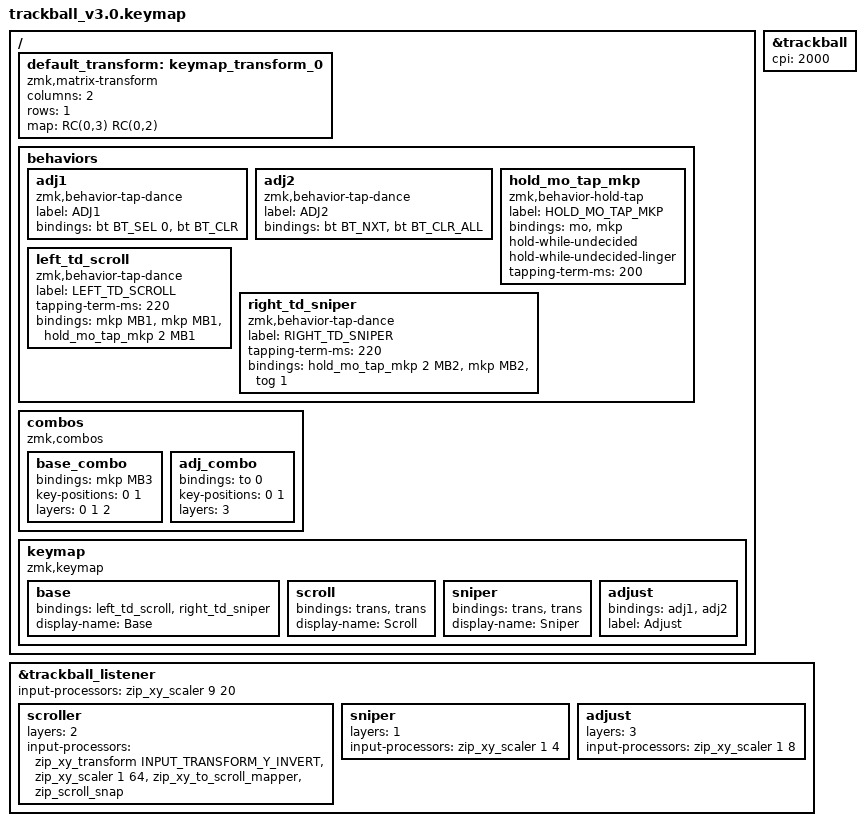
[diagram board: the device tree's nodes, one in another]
#include "keys_ru.h"
#include <dt-bindings/zmk/input_transform.h>
#include <input/processors.dtsi>
#include <zephyr/dt-bindings/input/input-event-codes.h>
#include <dt-bindings/zmk/matrix_transform.h>
#include <scroll-snap.dtsi>
#include <behaviors.dtsi>
#include <dt-bindings/zmk/bt.h>
#include <dt-bindings/zmk/pointing.h>

/ {
    default_transform: keymap_transform_0 {
        compatible = "zmk,matrix-transform";
        columns = <2>;
        rows = <1>;
        map = <
            RC(0,3) RC(0,2)
        >;
    };

    behaviors {
        adj1: adj1 {
            compatible = "zmk,behavior-tap-dance";
            label = "ADJ1";
            #binding-cells = <0>;
            bindings = <&bt BT_SEL 0>, <&bt BT_CLR>;
        };

        adj2: adj2 {
            compatible = "zmk,behavior-tap-dance";
            label = "ADJ2";
            #binding-cells = <0>;
            bindings = <&bt BT_NXT>, <&bt BT_CLR_ALL>;
        };

        hold_mo_tap_mkp: hold_mo_tap_mkp {
            compatible = "zmk,behavior-hold-tap";
            label = "HOLD_MO_TAP_MKP";
            bindings = <&mo>, <&mkp>;
            #binding-cells = <2>;
            hold-while-undecided;
            hold-while-undecided-linger;
            tapping-term-ms = <200>;
        };

        /* ЛКМ:
           1 тап = ЛКМ
           2 тап = ЛКМ
           3-й тап:
             - быстро отпустил = ЛКМ
             - удержал = scroll layer 2, пока держишь
        */
        left_td_scroll: left_td_scroll {
            compatible = "zmk,behavior-tap-dance";
            label = "LEFT_TD_SCROLL";
            #binding-cells = <0>;
            tapping-term-ms = <220>;
            bindings = <
                &mkp MB1
                &mkp MB1
                &hold_mo_tap_mkp 2 MB1
            >;
        };

        /* ПКМ:
           1-й шаг = обычный ПКМ / hold = scroll layer 2
           2-й тап = обычный ПКМ
           3-й тап = toggle sniper layer 1
        */
        right_td_sniper: right_td_sniper {
            compatible = "zmk,behavior-tap-dance";
            label = "RIGHT_TD_SNIPER";
            #binding-cells = <0>;
            tapping-term-ms = <220>;
            bindings = <
                &hold_mo_tap_mkp 2 MB2
                &mkp MB2
                &tog 1
            >;
        };
    };

    combos {
        compatible = "zmk,combos";

        /* Две кнопки вместе = средняя кнопка */
        base_combo {
            bindings = <&mkp MB3>;
            key-positions = <0 1>;
            layers = <0 1 2>;
        };

        adj_combo {
            bindings = <&to 0>;
            key-positions = <0 1>;
            layers = <3>;
        };
    };

    keymap {
        compatible = "zmk,keymap";

        base {
            bindings = <
                &left_td_scroll  &right_td_sniper
            >;

            display-name = "Base";
        };

        scroll {
            bindings = <
                &trans  &trans
            >;

            display-name = "Scroll";
        };

        sniper {
            bindings = <
                &trans  &trans
            >;

            display-name = "Sniper";
        };

        adjust {
            bindings = <
                &adj1  &adj2
            >;

            label = "Adjust";
        };
    };
};

&trackball { cpi = <2000>; };

&trackball_listener {
    input-processors = <&zip_xy_scaler 9 20>;

    /* scroll layer */
    scroller {
        layers = <2>;
        input-processors =
            <&zip_xy_transform INPUT_TRANSFORM_Y_INVERT>,
            <&zip_xy_scaler 1 64>,
            <&zip_xy_to_scroll_mapper &zip_scroll_snap>;
    };

    /* sniper layer */
    sniper {
        layers = <1>;
        input-processors = <&zip_xy_scaler 1 4>;
    };

    adjust {
        layers = <3>;
        input-processors = <&zip_xy_scaler 1 8>;
    };
};
